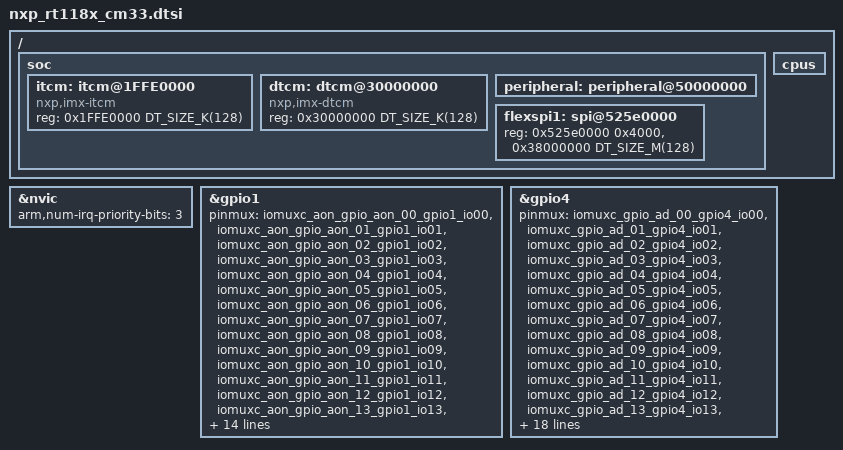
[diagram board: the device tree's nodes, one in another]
/*
 * Copyright 2024 NXP
 *
 * SPDX-License-Identifier: Apache-2.0
 */

#include <arm/armv8-m.dtsi>
#include <mem.h>
#include <zephyr/dt-bindings/memory-attr/memory-attr-arm.h>

/ {
	soc {
		itcm: itcm@1FFE0000 {
			compatible = "nxp,imx-itcm";
			reg = <0x1FFE0000 DT_SIZE_K(128)>;
		};

		dtcm: dtcm@30000000 {
			compatible = "nxp,imx-dtcm";
			reg = <0x30000000 DT_SIZE_K(128)>;
		};

		peripheral: peripheral@50000000 {
			ranges = <0x0 0x50000000 0x10000000>;
		};

		flexspi1: spi@525e0000 {
			reg = <0x525e0000 0x4000>,<0x38000000 DT_SIZE_M(128)>;
		};
	};
};

#include <nxp/nxp_rt118x.dtsi>

/ {
	cpus {
		/delete-node/ cpu@1;
	};
};

&nvic {
	arm,num-irq-priority-bits = <3>;
};

/*
 * GPIO pinmux options. These options define the pinmux settings
 * for GPIO ports on the package, so that the GPIO driver can
 * select GPIO mux options during GPIO configuration.
 */

&gpio1{
	pinmux = <&iomuxc_aon_gpio_aon_00_gpio1_io00>,
	    <&iomuxc_aon_gpio_aon_01_gpio1_io01>,
		<&iomuxc_aon_gpio_aon_02_gpio1_io02>,
		<&iomuxc_aon_gpio_aon_03_gpio1_io03>,
		<&iomuxc_aon_gpio_aon_04_gpio1_io04>,
		<&iomuxc_aon_gpio_aon_05_gpio1_io05>,
		<&iomuxc_aon_gpio_aon_06_gpio1_io06>,
		<&iomuxc_aon_gpio_aon_07_gpio1_io07>,
		<&iomuxc_aon_gpio_aon_08_gpio1_io08>,
		<&iomuxc_aon_gpio_aon_09_gpio1_io09>,
		<&iomuxc_aon_gpio_aon_10_gpio1_io10>,
		<&iomuxc_aon_gpio_aon_11_gpio1_io11>,
		<&iomuxc_aon_gpio_aon_12_gpio1_io12>,
		<&iomuxc_aon_gpio_aon_13_gpio1_io13>,
		<&iomuxc_aon_gpio_aon_14_gpio1_io14>,
		<&iomuxc_aon_gpio_aon_15_gpio1_io15>,
		<&iomuxc_aon_gpio_aon_16_gpio1_io16>,
		<&iomuxc_aon_gpio_aon_17_gpio1_io17>,
		<&iomuxc_aon_gpio_aon_18_gpio1_io18>,
		<&iomuxc_aon_gpio_aon_19_gpio1_io19>,
		<&iomuxc_aon_gpio_aon_20_gpio1_io20>,
		<&iomuxc_aon_gpio_aon_21_gpio1_io21>,
		<&iomuxc_aon_gpio_aon_22_gpio1_io22>,
		<&iomuxc_aon_gpio_aon_23_gpio1_io23>,
		<&iomuxc_aon_gpio_aon_24_gpio1_io24>,
		<&iomuxc_aon_gpio_aon_25_gpio1_io25>,
		<&iomuxc_aon_gpio_aon_26_gpio1_io26>,
		<&iomuxc_aon_gpio_aon_27_gpio1_io27>;
};

&gpio4{
	pinmux = <&iomuxc_gpio_ad_00_gpio4_io00>,
		<&iomuxc_gpio_ad_01_gpio4_io01>,
		<&iomuxc_gpio_ad_02_gpio4_io02>,
		<&iomuxc_gpio_ad_03_gpio4_io03>,
		<&iomuxc_gpio_ad_04_gpio4_io04>,
		<&iomuxc_gpio_ad_05_gpio4_io05>,
		<&iomuxc_gpio_ad_06_gpio4_io06>,
		<&iomuxc_gpio_ad_07_gpio4_io07>,
		<&iomuxc_gpio_ad_08_gpio4_io08>,
		<&iomuxc_gpio_ad_09_gpio4_io09>,
		<&iomuxc_gpio_ad_10_gpio4_io10>,
		<&iomuxc_gpio_ad_11_gpio4_io11>,
		<&iomuxc_gpio_ad_12_gpio4_io12>,
		<&iomuxc_gpio_ad_13_gpio4_io13>,
		<&iomuxc_gpio_ad_14_gpio4_io14>,
		<&iomuxc_gpio_ad_15_gpio4_io15>,
		<&iomuxc_gpio_ad_16_gpio4_io16>,
		<&iomuxc_gpio_ad_17_gpio4_io17>,
		<&iomuxc_gpio_ad_18_gpio4_io18>,
		<&iomuxc_gpio_ad_19_gpio4_io19>,
		<&iomuxc_gpio_ad_20_gpio4_io20>,
		<&iomuxc_gpio_ad_21_gpio4_io21>,
		<&iomuxc_gpio_ad_22_gpio4_io22>,
		<&iomuxc_gpio_ad_23_gpio4_io23>,
		<&iomuxc_gpio_ad_24_gpio4_io24>,
		<&iomuxc_gpio_ad_25_gpio4_io25>,
		<&iomuxc_gpio_ad_26_gpio4_io26>,
		<&iomuxc_gpio_ad_27_gpio4_io27>,
		<&iomuxc_gpio_ad_28_gpio4_io28>,
		<&iomuxc_gpio_ad_29_gpio4_io29>,
		<&iomuxc_gpio_ad_30_gpio4_io30>,
		<&iomuxc_gpio_ad_31_gpio4_io31>;
};
